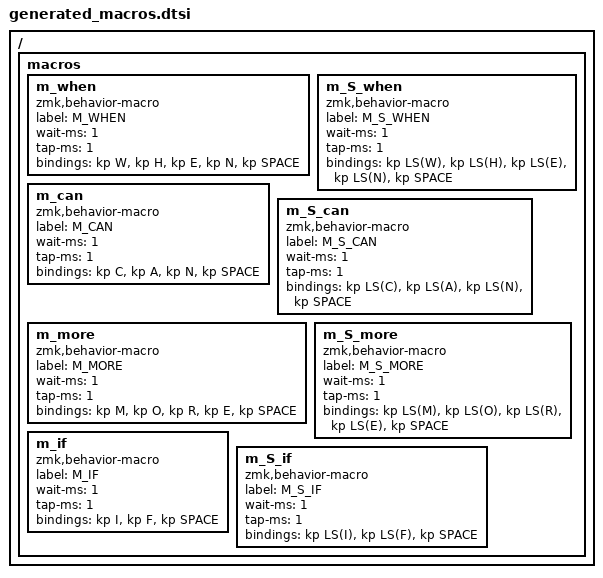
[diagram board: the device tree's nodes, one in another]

/*
 * Generated ZMK Macros from chords/jocke_chords.json
 * Automatically included by glove80.keymap
 * DO NOT EDIT MANUALLY
 */

/ {
    macros {

        m_when: m_when { // Output: 'when' + SPACE
            compatible = "zmk,behavior-macro";
            label = "M_WHEN";
            #binding-cells = <0>;
            wait-ms = <1>; // Adjust timing if needed
            tap-ms = <1>;
            bindings = <&kp W &kp H &kp E &kp N &kp SPACE>;
        };
        m_S_when: m_S_when { // Shifted Output: 'when' + SPACE
            compatible = "zmk,behavior-macro";
            label = "M_S_WHEN";
            #binding-cells = <0>;
            wait-ms = <1>;
            tap-ms = <1>;
            bindings = <&kp LS(W) &kp LS(H) &kp LS(E) &kp LS(N) &kp SPACE>;
        };
        m_can: m_can { // Output: 'can' + SPACE
            compatible = "zmk,behavior-macro";
            label = "M_CAN";
            #binding-cells = <0>;
            wait-ms = <1>; // Adjust timing if needed
            tap-ms = <1>;
            bindings = <&kp C &kp A &kp N &kp SPACE>;
        };
        m_S_can: m_S_can { // Shifted Output: 'can' + SPACE
            compatible = "zmk,behavior-macro";
            label = "M_S_CAN";
            #binding-cells = <0>;
            wait-ms = <1>;
            tap-ms = <1>;
            bindings = <&kp LS(C) &kp LS(A) &kp LS(N) &kp SPACE>;
        };
        m_more: m_more { // Output: 'more' + SPACE
            compatible = "zmk,behavior-macro";
            label = "M_MORE";
            #binding-cells = <0>;
            wait-ms = <1>; // Adjust timing if needed
            tap-ms = <1>;
            bindings = <&kp M &kp O &kp R &kp E &kp SPACE>;
        };
        m_S_more: m_S_more { // Shifted Output: 'more' + SPACE
            compatible = "zmk,behavior-macro";
            label = "M_S_MORE";
            #binding-cells = <0>;
            wait-ms = <1>;
            tap-ms = <1>;
            bindings = <&kp LS(M) &kp LS(O) &kp LS(R) &kp LS(E) &kp SPACE>;
        };
        m_if: m_if { // Output: 'if' + SPACE
            compatible = "zmk,behavior-macro";
            label = "M_IF";
            #binding-cells = <0>;
            wait-ms = <1>; // Adjust timing if needed
            tap-ms = <1>;
            bindings = <&kp I &kp F &kp SPACE>;
        };
        m_S_if: m_S_if { // Shifted Output: 'if' + SPACE
            compatible = "zmk,behavior-macro";
            label = "M_S_IF";
            #binding-cells = <0>;
            wait-ms = <1>;
            tap-ms = <1>;
            bindings = <&kp LS(I) &kp LS(F) &kp SPACE>;
        };
    }; // end of macros
}; // end of /
